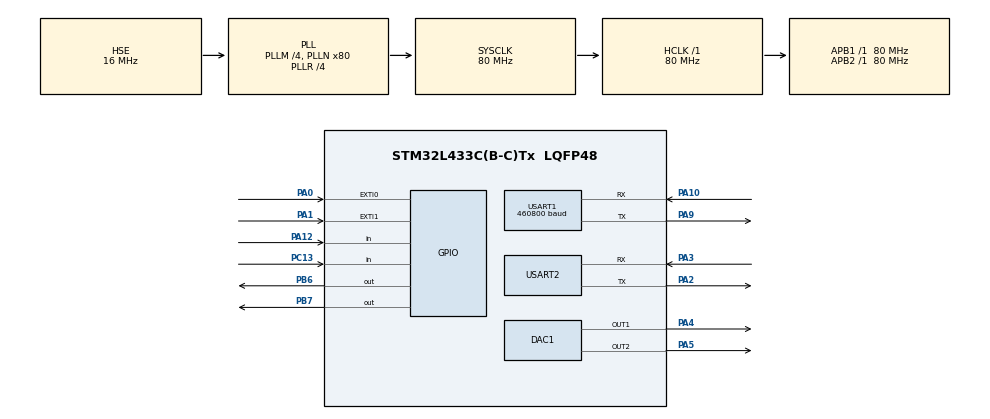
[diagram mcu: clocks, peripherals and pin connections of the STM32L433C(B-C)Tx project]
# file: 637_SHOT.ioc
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ADC1.Channel-0\#ChannelRegularConversion=ADC_CHANNEL_TEMPSENSOR
ADC1.NbrOfConversionFlag=1
ADC1.OffsetNumber-0\#ChannelRegularConversion=ADC_OFFSET_NONE
ADC1.Rank-0\#ChannelRegularConversion=1
ADC1.SamplingTime-0\#ChannelRegularConversion=ADC_SAMPLETIME_2CYCLES_5
ADC1.master=1
DAC1.DAC_Channel-DAC_OUT2=DAC_CHANNEL_2
Mcu.Family=STM32L4
Mcu.Name=STM32L433C(B-C)Tx
Mcu.Package=LQFP48
NVIC.PriorityGroup=NVIC_PRIORITYGROUP_4
NVIC.TIM1_BRK_TIM15_IRQn=true\:0\:0\:false\:false\:true\:true\:true
PA0.Signal=GPXTI0
PA1.Signal=GPXTI1
PA10.Mode=Asynchronous
PA10.Signal=USART1_RX
PA12.Signal=GPIO_Input
PA2.Mode=Asynchronous
PA2.Signal=USART2_TX
PA3.Mode=Asynchronous
PA3.Signal=USART2_RX
PA4.Signal=COMP_DAC11_group
PA5.Signal=COMP_DAC12_group
PA9.Mode=Asynchronous
PA9.Signal=USART1_TX
PB6.Signal=GPIO_Output
PB7.Signal=GPIO_Output
PC13.Signal=GPIO_Input
PH0-OSC_IN\ (PH0).Mode=HSE-External-Oscillator
PH0-OSC_IN\ (PH0).Signal=RCC_OSC_IN
PH1-OSC_OUT\ (PH1).Mode=HSE-External-Oscillator
PH1-OSC_OUT\ (PH1).Signal=RCC_OSC_OUT
ProjectManager.HeapSize=0x200
ProjectManager.StackSize=0x400
ProjectManager.TargetToolchain=MDK-ARM V5.32
RCC.ADCFreq_Value=32000000
RCC.AHBFreq_Value=80000000
RCC.APB1Freq_Value=80000000
RCC.APB1TimFreq_Value=80000000
RCC.APB2Freq_Value=80000000
RCC.APB2TimFreq_Value=80000000
RCC.CortexFreq_Value=80000000
RCC.HCLKFreq_Value=80000000
RCC.HSE_VALUE=16000000
RCC.HSI48_VALUE=48000000
RCC.HSI_VALUE=16000000
RCC.LSE_VALUE=32768
RCC.MSI_VALUE=4000000
RCC.PLLM=4
RCC.PLLN=80
RCC.PLLR=RCC_PLLR_DIV4
RCC.PLLSAI1N=16
RCC.PLLSourceVirtual=RCC_PLLSOURCE_HSE
RCC.SYSCLKFreq_VALUE=80000000
RCC.SYSCLKSource=RCC_SYSCLKSOURCE_PLLCLK
RCC.USART1CLockSelection=RCC_USART1CLKSOURCE_HSI
RCC.USBFreq_Value=32000000
RCC.VCOOutputFreq_Value=320000000
SH.COMP_DAC11_group.0=DAC1_OUT1,DAC_OUT1
SH.COMP_DAC12_group.0=DAC1_OUT2,DAC_OUT2
USART1.BaudRate=460800
USART1.VirtualMode-Asynchronous=VM_ASYNC
USART2.VirtualMode-Asynchronous=VM_ASYNC
VP_ADC1_TempSens_Input.Mode=IN-TempSens
VP_ADC1_Vbat_Input.Mode=IN-Vbat
VP_TIM15_VS_ClockSourceINT.Mode=Internal
VP_TIM15_VS_OPM.Mode=OPM_bit
VP_TIM16_VS_ClockSourceINT.Mode=Enable_Timer
VP_TIM6_VS_ClockSourceINT.Mode=Enable_Timer
VP_TIM6_VS_OPM.Mode=OPM_bit
VP_TIM7_VS_ClockSourceINT.Mode=Enable_Timer
VP_TIM7_VS_OPM.Mode=OPM_bit
board=custom

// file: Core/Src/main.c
/* USER CODE BEGIN Header */
/**
  ******************************************************************************
  * @file           : main.c
  * @brief          : Main program body
  ******************************************************************************
  * @attention
  *
  * Copyright (c) 2024 STMicroelectronics.
  * All rights reserved.
  *
  * This software is licensed under terms that can be found in the LICENSE file
  * in the root directory of this software component.
  * If no LICENSE file comes with this software, it is provided AS-IS.
  *
  ******************************************************************************
  */
/* USER CODE END Header */
#include "main.h"

ADC_HandleTypeDef hadc1;

DAC_HandleTypeDef hdac1;

TIM_HandleTypeDef htim6;
TIM_HandleTypeDef htim7;
TIM_HandleTypeDef htim15;
TIM_HandleTypeDef htim16;

UART_HandleTypeDef huart1;
UART_HandleTypeDef huart2;

void SystemClock_Config(void);
static void MX_GPIO_Init(void);
static void MX_ADC1_Init(void);
static void MX_DAC1_Init(void);
static void MX_TIM6_Init(void);
static void MX_TIM7_Init(void);
static void MX_TIM15_Init(void);
static void MX_TIM16_Init(void);
static void MX_USART1_UART_Init(void);
static void MX_USART2_UART_Init(void);

int main(void)
{

  /* MCU Configuration--------------------------------------------------------*/

  /* Reset of all peripherals, Initializes the Flash interface and the Systick. */
  HAL_Init();

  /* Configure the system clock */
  SystemClock_Config();

  /* Initialize all configured peripherals */
  MX_GPIO_Init();
  MX_ADC1_Init();
  MX_DAC1_Init();
  MX_TIM6_Init();
  MX_TIM7_Init();
  MX_TIM15_Init();
  MX_TIM16_Init();
  MX_USART1_UART_Init();
  MX_USART2_UART_Init();

  /* Infinite loop */
  while (1)
  {

    /* USER CODE BEGIN 3 */
		// DAC ____________________
		// 4095 - MAX VALUE 0xFFF
		// 0 - MIN VALUE
		DAC->DHR12R1 = 0xFFF;

		// GPIO_EXT _______________
		// Register RTSR1 for FRONT
		// EXTI_RTSR1_RT0 == 0x00000001
		EXTI->RTSR1 |= EXTI_RTSR1_RT0;
		// Register FTSR1 for Spad
		EXTI->FTSR1 |= EXTI_FTSR1_FT0;

		// on prerivanie for pin GPIO_EXT
		EXTI->IMR1 |= EXTI_IMR1_IM0;

	}
  /* USER CODE END 3 */
}

void SystemClock_Config(void)
{
  RCC_OscInitTypeDef RCC_OscInitStruct = {0};
  RCC_ClkInitTypeDef RCC_ClkInitStruct = {0};

  /** Configure the main internal regulator output voltage
  */
  if (HAL_PWREx_ControlVoltageScaling(PWR_REGULATOR_VOLTAGE_SCALE1) != HAL_OK)
  {
    Error_Handler();
  }
  /** Initializes the RCC Oscillators according to the specified parameters
  * in the RCC_OscInitTypeDef structure.
  */
  RCC_OscInitStruct.OscillatorType = RCC_OSCILLATORTYPE_HSI|RCC_OSCILLATORTYPE_HSE;
  RCC_OscInitStruct.HSEState = RCC_HSE_ON;
  RCC_OscInitStruct.HSIState = RCC_HSI_ON;
  RCC_OscInitStruct.HSICalibrationValue = RCC_HSICALIBRATION_DEFAULT;
  RCC_OscInitStruct.PLL.PLLState = RCC_PLL_ON;
  RCC_OscInitStruct.PLL.PLLSource = RCC_PLLSOURCE_HSE;
  RCC_OscInitStruct.PLL.PLLM = 4;
  RCC_OscInitStruct.PLL.PLLN = 80;
  RCC_OscInitStruct.PLL.PLLP = RCC_PLLP_DIV7;
  RCC_OscInitStruct.PLL.PLLQ = RCC_PLLQ_DIV2;
  RCC_OscInitStruct.PLL.PLLR = RCC_PLLR_DIV4;
  if (HAL_RCC_OscConfig(&RCC_OscInitStruct) != HAL_OK)
  {
    Error_Handler();
  }
  /** Initializes the CPU, AHB and APB buses clocks
  */
  RCC_ClkInitStruct.ClockType = RCC_CLOCKTYPE_HCLK|RCC_CLOCKTYPE_SYSCLK
                              |RCC_CLOCKTYPE_PCLK1|RCC_CLOCKTYPE_PCLK2;
  RCC_ClkInitStruct.SYSCLKSource = RCC_SYSCLKSOURCE_PLLCLK;
  RCC_ClkInitStruct.AHBCLKDivider = RCC_SYSCLK_DIV1;
  RCC_ClkInitStruct.APB1CLKDivider = RCC_HCLK_DIV1;
  RCC_ClkInitStruct.APB2CLKDivider = RCC_HCLK_DIV1;

  if (HAL_RCC_ClockConfig(&RCC_ClkInitStruct, FLASH_LATENCY_4) != HAL_OK)
  {
    Error_Handler();
  }
}

static void MX_ADC1_Init(void)
{

  ADC_ChannelConfTypeDef sConfig = {0};

  /** Common config
  */
  hadc1.Instance = ADC1;
  hadc1.Init.ClockPrescaler = ADC_CLOCK_ASYNC_DIV1;
  hadc1.Init.Resolution = ADC_RESOLUTION_12B;
  hadc1.Init.DataAlign = ADC_DATAALIGN_RIGHT;
  hadc1.Init.ScanConvMode = ADC_SCAN_DISABLE;
  hadc1.Init.EOCSelection = ADC_EOC_SINGLE_CONV;
  hadc1.Init.LowPowerAutoWait = DISABLE;
  hadc1.Init.ContinuousConvMode = DISABLE;
  hadc1.Init.NbrOfConversion = 1;
  hadc1.Init.DiscontinuousConvMode = DISABLE;
  hadc1.Init.ExternalTrigConv = ADC_SOFTWARE_START;
  hadc1.Init.ExternalTrigConvEdge = ADC_EXTERNALTRIGCONVEDGE_NONE;
  hadc1.Init.DMAContinuousRequests = DISABLE;
  hadc1.Init.Overrun = ADC_OVR_DATA_PRESERVED;
  hadc1.Init.OversamplingMode = DISABLE;
  if (HAL_ADC_Init(&hadc1) != HAL_OK)
  {
    Error_Handler();
  }
  /** Configure Regular Channel
  */
  sConfig.Channel = ADC_CHANNEL_TEMPSENSOR;
  sConfig.Rank = ADC_REGULAR_RANK_1;
  sConfig.SamplingTime = ADC_SAMPLETIME_2CYCLES_5;
  sConfig.SingleDiff = ADC_SINGLE_ENDED;
  sConfig.OffsetNumber = ADC_OFFSET_NONE;
  sConfig.Offset = 0;
  if (HAL_ADC_ConfigChannel(&hadc1, &sConfig) != HAL_OK)
  {
    Error_Handler();
  }

}

static void MX_DAC1_Init(void)
{

  DAC_ChannelConfTypeDef sConfig = {0};

  /** DAC Initialization
  */
  hdac1.Instance = DAC1;
  if (HAL_DAC_Init(&hdac1) != HAL_OK)
  {
    Error_Handler();
  }
  /** DAC channel OUT1 config
  */
  sConfig.DAC_SampleAndHold = DAC_SAMPLEANDHOLD_DISABLE;
  sConfig.DAC_Trigger = DAC_TRIGGER_NONE;
  sConfig.DAC_OutputBuffer = DAC_OUTPUTBUFFER_ENABLE;
  sConfig.DAC_ConnectOnChipPeripheral = DAC_CHIPCONNECT_DISABLE;
  sConfig.DAC_UserTrimming = DAC_TRIMMING_FACTORY;
  if (HAL_DAC_ConfigChannel(&hdac1, &sConfig, DAC_CHANNEL_1) != HAL_OK)
  {
    Error_Handler();
  }
  /** DAC channel OUT2 config
  */
  if (HAL_DAC_ConfigChannel(&hdac1, &sConfig, DAC_CHANNEL_2) != HAL_OK)
  {
    Error_Handler();
  }

}

static void MX_TIM6_Init(void)
{

  TIM_MasterConfigTypeDef sMasterConfig = {0};

  htim6.Instance = TIM6;
  htim6.Init.Prescaler = 0;
  htim6.Init.CounterMode = TIM_COUNTERMODE_UP;
  htim6.Init.Period = 65535;
  htim6.Init.AutoReloadPreload = TIM_AUTORELOAD_PRELOAD_DISABLE;
  if (HAL_TIM_Base_Init(&htim6) != HAL_OK)
  {
    Error_Handler();
  }
  if (HAL_TIM_OnePulse_Init(&htim6, TIM_OPMODE_SINGLE) != HAL_OK)
  {
    Error_Handler();
  }
  sMasterConfig.MasterOutputTrigger = TIM_TRGO_RESET;
  sMasterConfig.MasterSlaveMode = TIM_MASTERSLAVEMODE_DISABLE;
  if (HAL_TIMEx_MasterConfigSynchronization(&htim6, &sMasterConfig) != HAL_OK)
  {
    Error_Handler();
  }

}

static void MX_TIM7_Init(void)
{

  TIM_MasterConfigTypeDef sMasterConfig = {0};

  htim7.Instance = TIM7;
  htim7.Init.Prescaler = 0;
  htim7.Init.CounterMode = TIM_COUNTERMODE_UP;
  htim7.Init.Period = 65535;
  htim7.Init.AutoReloadPreload = TIM_AUTORELOAD_PRELOAD_DISABLE;
  if (HAL_TIM_Base_Init(&htim7) != HAL_OK)
  {
    Error_Handler();
  }
  if (HAL_TIM_OnePulse_Init(&htim7, TIM_OPMODE_SINGLE) != HAL_OK)
  {
    Error_Handler();
  }
  sMasterConfig.MasterOutputTrigger = TIM_TRGO_RESET;
  sMasterConfig.MasterSlaveMode = TIM_MASTERSLAVEMODE_DISABLE;
  if (HAL_TIMEx_MasterConfigSynchronization(&htim7, &sMasterConfig) != HAL_OK)
  {
    Error_Handler();
  }

}

static void MX_TIM15_Init(void)
{

  TIM_ClockConfigTypeDef sClockSourceConfig = {0};
  TIM_MasterConfigTypeDef sMasterConfig = {0};

  htim15.Instance = TIM15;
  htim15.Init.Prescaler = 0;
  htim15.Init.CounterMode = TIM_COUNTERMODE_UP;
  htim15.Init.Period = 65535;
  htim15.Init.ClockDivision = TIM_CLOCKDIVISION_DIV1;
  htim15.Init.RepetitionCounter = 0;
  htim15.Init.AutoReloadPreload = TIM_AUTORELOAD_PRELOAD_DISABLE;
  if (HAL_TIM_Base_Init(&htim15) != HAL_OK)
  {
    Error_Handler();
  }
  sClockSourceConfig.ClockSource = TIM_CLOCKSOURCE_INTERNAL;
  if (HAL_TIM_ConfigClockSource(&htim15, &sClockSourceConfig) != HAL_OK)
  {
    Error_Handler();
  }
  if (HAL_TIM_OnePulse_Init(&htim15, TIM_OPMODE_SINGLE) != HAL_OK)
  {
    Error_Handler();
  }
  sMasterConfig.MasterOutputTrigger = TIM_TRGO_RESET;
  sMasterConfig.MasterSlaveMode = TIM_MASTERSLAVEMODE_DISABLE;
  if (HAL_TIMEx_MasterConfigSynchronization(&htim15, &sMasterConfig) != HAL_OK)
  {
    Error_Handler();
  }

}

static void MX_TIM16_Init(void)
{

  htim16.Instance = TIM16;
  htim16.Init.Prescaler = 0;
  htim16.Init.CounterMode = TIM_COUNTERMODE_UP;
  htim16.Init.Period = 65535;
  htim16.Init.ClockDivision = TIM_CLOCKDIVISION_DIV1;
  htim16.Init.RepetitionCounter = 0;
  htim16.Init.AutoReloadPreload = TIM_AUTORELOAD_PRELOAD_DISABLE;
  if (HAL_TIM_Base_Init(&htim16) != HAL_OK)
  {
    Error_Handler();
  }

}

static void MX_USART1_UART_Init(void)
{

  huart1.Instance = USART1;
  huart1.Init.BaudRate = 460800;
  huart1.Init.WordLength = UART_WORDLENGTH_8B;
  huart1.Init.StopBits = UART_STOPBITS_1;
  huart1.Init.Parity = UART_PARITY_NONE;
  huart1.Init.Mode = UART_MODE_TX_RX;
  huart1.Init.HwFlowCtl = UART_HWCONTROL_NONE;
  huart1.Init.OverSampling = UART_OVERSAMPLING_16;
  huart1.Init.OneBitSampling = UART_ONE_BIT_SAMPLE_DISABLE;
  huart1.AdvancedInit.AdvFeatureInit = UART_ADVFEATURE_NO_INIT;
  if (HAL_UART_Init(&huart1) != HAL_OK)
  {
    Error_Handler();
  }

}

static void MX_USART2_UART_Init(void)
{

  huart2.Instance = USART2;
  huart2.Init.BaudRate = 115200;
  huart2.Init.WordLength = UART_WORDLENGTH_8B;
  huart2.Init.StopBits = UART_STOPBITS_1;
  huart2.Init.Parity = UART_PARITY_NONE;
  huart2.Init.Mode = UART_MODE_TX_RX;
  huart2.Init.HwFlowCtl = UART_HWCONTROL_NONE;
  huart2.Init.OverSampling = UART_OVERSAMPLING_16;
  huart2.Init.OneBitSampling = UART_ONE_BIT_SAMPLE_DISABLE;
  huart2.AdvancedInit.AdvFeatureInit = UART_ADVFEATURE_NO_INIT;
  if (HAL_UART_Init(&huart2) != HAL_OK)
  {
    Error_Handler();
  }

}

static void MX_GPIO_Init(void)
{
  GPIO_InitTypeDef GPIO_InitStruct = {0};

  /* GPIO Ports Clock Enable */
  __HAL_RCC_GPIOC_CLK_ENABLE();
  __HAL_RCC_GPIOH_CLK_ENABLE();
  __HAL_RCC_GPIOA_CLK_ENABLE();
  __HAL_RCC_GPIOB_CLK_ENABLE();

  /*Configure GPIO pin Output Level */
  HAL_GPIO_WritePin(GPIOB, GPIO_PIN_6|GPIO_PIN_7, GPIO_PIN_RESET);

  /*Configure GPIO pin : PC13 */
  GPIO_InitStruct.Pin = GPIO_PIN_13;
  GPIO_InitStruct.Mode = GPIO_MODE_INPUT;
  GPIO_InitStruct.Pull = GPIO_NOPULL;
  HAL_GPIO_Init(GPIOC, &GPIO_InitStruct);

  /*Configure GPIO pins : PA0 PA1 */
  GPIO_InitStruct.Pin = GPIO_PIN_0|GPIO_PIN_1;
  GPIO_InitStruct.Mode = GPIO_MODE_IT_RISING;
  GPIO_InitStruct.Pull = GPIO_NOPULL;
  HAL_GPIO_Init(GPIOA, &GPIO_InitStruct);

  /*Configure GPIO pin : PA12 */
  GPIO_InitStruct.Pin = GPIO_PIN_12;
  GPIO_InitStruct.Mode = GPIO_MODE_INPUT;
  GPIO_InitStruct.Pull = GPIO_NOPULL;
  HAL_GPIO_Init(GPIOA, &GPIO_InitStruct);

  /*Configure GPIO pins : PB6 PB7 */
  GPIO_InitStruct.Pin = GPIO_PIN_6|GPIO_PIN_7;
  GPIO_InitStruct.Mode = GPIO_MODE_OUTPUT_PP;
  GPIO_InitStruct.Pull = GPIO_NOPULL;
  GPIO_InitStruct.Speed = GPIO_SPEED_FREQ_LOW;
  HAL_GPIO_Init(GPIOB, &GPIO_InitStruct);

}

void Error_Handler(void)
{
  __disable_irq();
  while (1)
  {
  }
}
